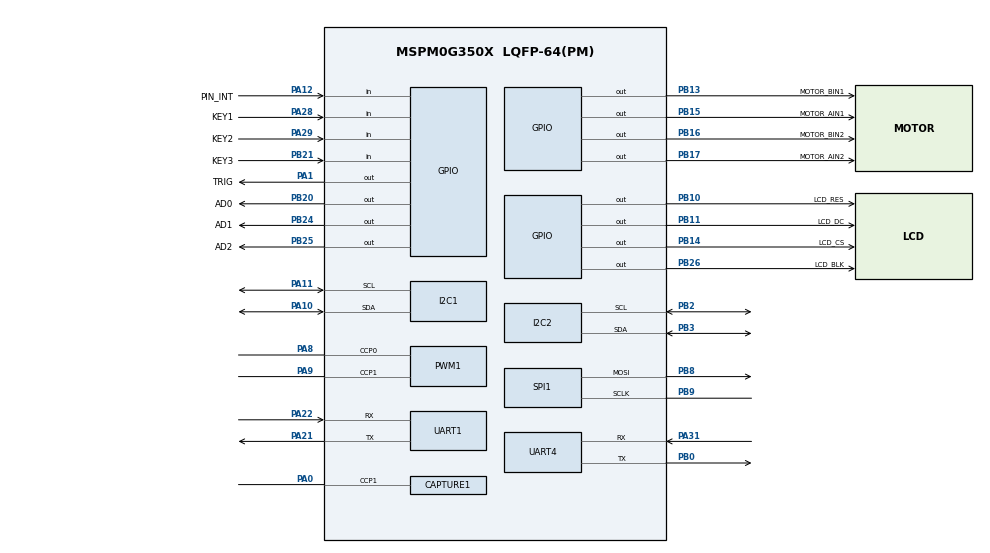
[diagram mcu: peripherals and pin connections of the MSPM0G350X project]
/**
 * @cliArgs --device "MSPM0G350X" --part "Default" --package "LQFP-64(PM)" --product "mspm0_sdk@2.10.00.04"
 * @versions {"tool":"1.26.2+4477"}
 */

/**
 * Import the modules used in this configuration.
 */
const ADC12    = scripting.addModule("/ti/driverlib/ADC12", {}, false);
const ADC121   = ADC12.addInstance();
const CAPTURE  = scripting.addModule("/ti/driverlib/CAPTURE", {}, false);
const CAPTURE1 = CAPTURE.addInstance();
const GPIO     = scripting.addModule("/ti/driverlib/GPIO", {}, false);
const GPIO1    = GPIO.addInstance();
const GPIO2    = GPIO.addInstance();
const GPIO3    = GPIO.addInstance();
const GPIO4    = GPIO.addInstance();
const GPIO5    = GPIO.addInstance();
const GPIO6    = GPIO.addInstance();
const GPIO7    = GPIO.addInstance();
const GPIO8    = GPIO.addInstance();
const I2C      = scripting.addModule("/ti/driverlib/I2C", {}, false);
const I2C1     = I2C.addInstance();
const I2C2     = I2C.addInstance();
const PWM      = scripting.addModule("/ti/driverlib/PWM", {}, false);
const PWM1     = PWM.addInstance();
const SPI      = scripting.addModule("/ti/driverlib/SPI", {}, false);
const SPI1     = SPI.addInstance();
const SYSCTL   = scripting.addModule("/ti/driverlib/SYSCTL");
const TIMER    = scripting.addModule("/ti/driverlib/TIMER", {}, false);
const TIMER1   = TIMER.addInstance();
const UART     = scripting.addModule("/ti/driverlib/UART", {}, false);
const UART1    = UART.addInstance();
const UART2    = UART.addInstance();
const UART3    = UART.addInstance();
const UART4    = UART.addInstance();

/**
 * Write custom configuration values to the imported modules.
 */
const divider6       = system.clockTree["PLL_CLK2X_DIV"];
divider6.divideValue = 4;

const divider7       = system.clockTree["PLL_PDIV"];
divider7.divideValue = 2;

const divider9       = system.clockTree["UDIV"];
divider9.divideValue = 2;

const multiplier2         = system.clockTree["PLL_QDIV"];
multiplier2.multiplyValue = 10;

const mux8       = system.clockTree["HSCLKMUX"];
mux8.inputSelect = "HSCLKMUX_SYSPLL2X";

ADC121.$name                      = "ADC12_0";
ADC121.sampleTime0                = "2 us";
ADC121.sampClkDiv                 = "DL_ADC12_CLOCK_DIVIDE_8";
ADC121.enabledInterrupts          = ["DL_ADC12_INTERRUPT_MEM0_RESULT_LOADED"];
ADC121.adcMem0_name               = "ADC_CH0";
ADC121.repeatMode                 = true;
ADC121.peripheral.$assign         = "ADC0";
ADC121.peripheral.adcPin0.$assign = "PA27";
ADC121.adcPin0Config.$name        = "ti_driverlib_gpio_GPIOPinGeneric8";

const Board = scripting.addModule("/ti/driverlib/Board", {}, false);

CAPTURE1.$name                      = "HC_SR04_CAPTURE";
CAPTURE1.ccIndex                    = 1;
CAPTURE1.captMode                   = "COMBINED";
CAPTURE1.timerClkPrescale           = 32;
CAPTURE1.timerPeriod                = "65.536 ms";
CAPTURE1.interrupts                 = ["CC1_DN"];
CAPTURE1.interruptPriority          = "2";
CAPTURE1.timerStartTimer            = true;
CAPTURE1.peripheral.$assign         = "TIMG8";
CAPTURE1.peripheral.ccp1Pin.$assign = "PA0";
CAPTURE1.ccp1PinConfig.$name        = "ti_driverlib_gpio_GPIOPinGeneric15";

GPIO1.port                               = "PORTA";
GPIO1.$name                              = "KEY_INPUT_A";
GPIO1.associatedPins.create(2);
GPIO1.associatedPins[0].$name            = "KEY1";
GPIO1.associatedPins[0].direction        = "INPUT";
GPIO1.associatedPins[0].internalResistor = "PULL_UP";
GPIO1.associatedPins[0].pin.$assign      = "PA28";
GPIO1.associatedPins[1].$name            = "KEY2";
GPIO1.associatedPins[1].direction        = "INPUT";
GPIO1.associatedPins[1].internalResistor = "PULL_UP";
GPIO1.associatedPins[1].pin.$assign      = "PA29";

GPIO2.$name                         = "MOTOR_AIN";
GPIO2.port                          = "PORTB";
GPIO2.associatedPins.create(2);
GPIO2.associatedPins[0].$name       = "MOTOR_AIN1";
GPIO2.associatedPins[0].pin.$assign = "PB15";
GPIO2.associatedPins[1].$name       = "MOTOR_AIN2";
GPIO2.associatedPins[1].pin.$assign = "PB17";

GPIO3.$name                         = "MOTOR_BIN";
GPIO3.port                          = "PORTB";
GPIO3.associatedPins.create(2);
GPIO3.associatedPins[0].$name       = "MOTOR_BIN1";
GPIO3.associatedPins[0].pin.$assign = "PB13";
GPIO3.associatedPins[1].$name       = "MOTOR_BIN2";
GPIO3.associatedPins[1].pin.$assign = "PB16";

GPIO4.$name                         = "Gray_Address";
GPIO4.port                          = "PORTB";
GPIO4.associatedPins.create(3);
GPIO4.associatedPins[0].$name       = "AD0";
GPIO4.associatedPins[0].pin.$assign = "PB20";
GPIO4.associatedPins[1].$name       = "AD1";
GPIO4.associatedPins[1].pin.$assign = "PB24";
GPIO4.associatedPins[2].$name       = "AD2";
GPIO4.associatedPins[2].pin.$assign = "PB25";

GPIO5.$name                               = "GPIO_MPU6050";
GPIO5.port                                = "PORTA";
GPIO5.associatedPins[0].$name             = "PIN_INT";
GPIO5.associatedPins[0].direction         = "INPUT";
GPIO5.associatedPins[0].interruptEn       = true;
GPIO5.associatedPins[0].interruptPriority = "1";
GPIO5.associatedPins[0].polarity          = "RISE";
GPIO5.associatedPins[0].pin.$assign       = "PA12";

GPIO6.$name                          = "GPIO_LCD_CONTROL";
GPIO6.port                           = "PORTB";
GPIO6.associatedPins.create(4);
GPIO6.associatedPins[0].$name        = "LCD_RES";
GPIO6.associatedPins[0].initialValue = "SET";
GPIO6.associatedPins[0].pin.$assign  = "PB10";
GPIO6.associatedPins[1].$name        = "LCD_DC";
GPIO6.associatedPins[1].initialValue = "SET";
GPIO6.associatedPins[1].pin.$assign  = "PB11";
GPIO6.associatedPins[2].$name        = "LCD_CS";
GPIO6.associatedPins[2].initialValue = "SET";
GPIO6.associatedPins[2].pin.$assign  = "PB14";
GPIO6.associatedPins[3].$name        = "LCD_BLK";
GPIO6.associatedPins[3].pin.$assign  = "PB26";

GPIO7.$name                              = "KEY_INPUT_B";
GPIO7.port                               = "PORTB";
GPIO7.portSegment                        = "Upper";
GPIO7.associatedPins[0].$name            = "KEY3";
GPIO7.associatedPins[0].direction        = "INPUT";
GPIO7.associatedPins[0].internalResistor = "PULL_UP";
GPIO7.associatedPins[0].pin.$assign      = "PB21";

GPIO8.$name                         = "HC_SR04_TRIG";
GPIO8.port                          = "PORTA";
GPIO8.associatedPins[0].$name       = "TRIG";
GPIO8.associatedPins[0].pin.$assign = "PA1";

I2C1.$name                             = "I2C_OLED";
I2C1.basicEnableController             = true;
I2C1.basicControllerStandardBusSpeed   = "Fast";
I2C1.peripheral.$assign                = "I2C0";
I2C1.peripheral.sdaPin.$assign         = "PA10";
I2C1.peripheral.sclPin.$assign         = "PA11";
I2C1.sdaPinConfig.$name                = "ti_driverlib_gpio_GPIOPinGeneric2";
I2C1.sdaPinConfig.hideOutputInversion  = scripting.forceWrite(false);
I2C1.sdaPinConfig.onlyInternalResistor = scripting.forceWrite(false);
I2C1.sdaPinConfig.passedPeripheralType = scripting.forceWrite("Digital");
I2C1.sclPinConfig.$name                = "ti_driverlib_gpio_GPIOPinGeneric3";
I2C1.sclPinConfig.hideOutputInversion  = scripting.forceWrite(false);
I2C1.sclPinConfig.onlyInternalResistor = scripting.forceWrite(false);
I2C1.sclPinConfig.passedPeripheralType = scripting.forceWrite("Digital");

I2C2.$name                             = "I2C_MPU6050";
I2C2.basicEnableController             = true;
I2C2.basicControllerStandardBusSpeed   = "Fast";
I2C2.peripheral.$assign                = "I2C1";
I2C2.peripheral.sdaPin.$assign         = "PB3";
I2C2.peripheral.sclPin.$assign         = "PB2";
I2C2.sdaPinConfig.$name                = "ti_driverlib_gpio_GPIOPinGeneric4";
I2C2.sdaPinConfig.hideOutputInversion  = scripting.forceWrite(false);
I2C2.sdaPinConfig.onlyInternalResistor = scripting.forceWrite(false);
I2C2.sdaPinConfig.passedPeripheralType = scripting.forceWrite("Digital");
I2C2.sclPinConfig.$name                = "ti_driverlib_gpio_GPIOPinGeneric5";
I2C2.sclPinConfig.hideOutputInversion  = scripting.forceWrite(false);
I2C2.sclPinConfig.onlyInternalResistor = scripting.forceWrite(false);
I2C2.sclPinConfig.passedPeripheralType = scripting.forceWrite("Digital");

PWM1.$name                              = "PWM_MOTOR";
PWM1.pwmMode                            = "EDGE_ALIGN_UP";
PWM1.timerStartTimer                    = true;
PWM1.peripheral.$assign                 = "TIMA0";
PWM1.peripheral.ccp0Pin.$assign         = "PA8";
PWM1.peripheral.ccp1Pin.$assign         = "PA9";
PWM1.PWM_CHANNEL_0.$name                = "ti_driverlib_pwm_PWMTimerCC0";
PWM1.PWM_CHANNEL_1.$name                = "ti_driverlib_pwm_PWMTimerCC1";
PWM1.ccp0PinConfig.direction            = scripting.forceWrite("OUTPUT");
PWM1.ccp0PinConfig.hideOutputInversion  = scripting.forceWrite(false);
PWM1.ccp0PinConfig.onlyInternalResistor = scripting.forceWrite(false);
PWM1.ccp0PinConfig.passedPeripheralType = scripting.forceWrite("Digital");
PWM1.ccp0PinConfig.$name                = "ti_driverlib_gpio_GPIOPinGeneric0";
PWM1.ccp1PinConfig.direction            = scripting.forceWrite("OUTPUT");
PWM1.ccp1PinConfig.hideOutputInversion  = scripting.forceWrite(false);
PWM1.ccp1PinConfig.onlyInternalResistor = scripting.forceWrite(false);
PWM1.ccp1PinConfig.passedPeripheralType = scripting.forceWrite("Digital");
PWM1.ccp1PinConfig.$name                = "ti_driverlib_gpio_GPIOPinGeneric1";

SPI1.$name                              = "SPI_LCD";
SPI1.frameFormat                        = "MOTO3";
SPI1.direction                          = "PICO";
SPI1.sclkPinConfig.direction            = scripting.forceWrite("OUTPUT");
SPI1.sclkPinConfig.onlyInternalResistor = scripting.forceWrite(false);
SPI1.sclkPinConfig.passedPeripheralType = scripting.forceWrite("Digital");
SPI1.sclkPinConfig.$name                = "ti_driverlib_gpio_GPIOPinGeneric13";
SPI1.mosiPinConfig.direction            = scripting.forceWrite("OUTPUT");
SPI1.mosiPinConfig.hideOutputInversion  = scripting.forceWrite(false);
SPI1.mosiPinConfig.onlyInternalResistor = scripting.forceWrite(false);
SPI1.mosiPinConfig.passedPeripheralType = scripting.forceWrite("Digital");
SPI1.mosiPinConfig.$name                = "ti_driverlib_gpio_GPIOPinGeneric14";
SPI1.peripheral.$assign                 = "SPI1";
SPI1.peripheral.sclkPin.$assign         = "PB9";
SPI1.peripheral.mosiPin.$assign         = "PB8";

SYSCTL.forceDefaultClkConfig = true;

TIMER1.timerMode          = "PERIODIC";
TIMER1.timerStartTimer    = true;
TIMER1.$name              = "CONTROL_TIMER";
TIMER1.timerPeriod        = "10ms";
TIMER1.timerClkDiv        = 8;
TIMER1.interrupts         = ["ZERO"];
TIMER1.interruptPriority  = "2";
TIMER1.peripheral.$assign = "TIMA1";

UART1.targetBaudRate                    = 115200;
UART1.enabledInterrupts                 = ["DMA_DONE_TX","EOT_DONE"];
UART1.interruptPriority                 = "3";
UART1.enableFIFO                        = true;
UART1.txFifoThreshold                   = "DL_UART_TX_FIFO_LEVEL_ONE_ENTRY";
UART1.enabledDMATXTriggers              = "DL_UART_DMA_INTERRUPT_TX";
UART1.$name                             = "UART_TEST";
UART1.peripheral.rxPin.$assign          = "PA22";
UART1.peripheral.txPin.$assign          = "PA21";
UART1.txPinConfig.direction             = scripting.forceWrite("OUTPUT");
UART1.txPinConfig.hideOutputInversion   = scripting.forceWrite(false);
UART1.txPinConfig.onlyInternalResistor  = scripting.forceWrite(false);
UART1.txPinConfig.passedPeripheralType  = scripting.forceWrite("Digital");
UART1.txPinConfig.$name                 = "ti_driverlib_gpio_GPIOPinGeneric6";
UART1.rxPinConfig.hideOutputInversion   = scripting.forceWrite(false);
UART1.rxPinConfig.onlyInternalResistor  = scripting.forceWrite(false);
UART1.rxPinConfig.passedPeripheralType  = scripting.forceWrite("Digital");
UART1.rxPinConfig.$name                 = "ti_driverlib_gpio_GPIOPinGeneric7";
UART1.DMA_CHANNEL_TX.$name              = "DMA_CH0";
UART1.DMA_CHANNEL_TX.addressMode        = "b2f";
UART1.DMA_CHANNEL_TX.dstLength          = "BYTE";
UART1.DMA_CHANNEL_TX.srcLength          = "BYTE";
UART1.DMA_CHANNEL_TX.peripheral.$assign = "DMA_CH0";

UART2.$name                            = "UART_MAXI";
UART2.targetBaudRate                   = 115200;
UART2.peripheral.$assign               = "UART1";
UART2.txPinConfig.direction            = scripting.forceWrite("OUTPUT");
UART2.txPinConfig.hideOutputInversion  = scripting.forceWrite(false);
UART2.txPinConfig.onlyInternalResistor = scripting.forceWrite(false);
UART2.txPinConfig.passedPeripheralType = scripting.forceWrite("Digital");
UART2.txPinConfig.$name                = "ti_driverlib_gpio_GPIOPinGeneric9";
UART2.rxPinConfig.hideOutputInversion  = scripting.forceWrite(false);
UART2.rxPinConfig.onlyInternalResistor = scripting.forceWrite(false);
UART2.rxPinConfig.passedPeripheralType = scripting.forceWrite("Digital");
UART2.rxPinConfig.$name                = "ti_driverlib_gpio_GPIOPinGeneric10";

UART3.$name                            = "UART_BLUETOOTH";
UART3.targetBaudRate                   = 115200;
UART3.enabledInterrupts                = ["RX"];
UART3.interruptPriority                = "3";
UART3.enableFIFO                       = true;
UART3.rxFifoThreshold                  = "DL_UART_RX_FIFO_LEVEL_ONE_ENTRY";
UART3.peripheral.$assign               = "UART3";
UART3.txPinConfig.direction            = scripting.forceWrite("OUTPUT");
UART3.txPinConfig.hideOutputInversion  = scripting.forceWrite(false);
UART3.txPinConfig.onlyInternalResistor = scripting.forceWrite(false);
UART3.txPinConfig.passedPeripheralType = scripting.forceWrite("Digital");
UART3.txPinConfig.$name                = "ti_driverlib_gpio_GPIOPinGeneric11";
UART3.rxPinConfig.hideOutputInversion  = scripting.forceWrite(false);
UART3.rxPinConfig.onlyInternalResistor = scripting.forceWrite(false);
UART3.rxPinConfig.passedPeripheralType = scripting.forceWrite("Digital");
UART3.rxPinConfig.$name                = "ti_driverlib_gpio_GPIOPinGeneric12";

UART4.$name                            = "UART_GYRO";
UART4.targetBaudRate                   = 115200;
UART4.enabledInterrupts                = ["RX"];
UART4.interruptPriority                = "3";
UART4.enableFIFO                       = true;
UART4.rxFifoThreshold                  = "DL_UART_RX_FIFO_LEVEL_ONE_ENTRY";
UART4.peripheral.$assign               = "UART0";
UART4.peripheral.rxPin.$assign         = "PA31";
UART4.peripheral.txPin.$assign         = "PB0";
UART4.txPinConfig.$name                = "ti_driverlib_gpio_GPIOPinGeneric16";
UART4.txPinConfig.direction            = scripting.forceWrite("OUTPUT");
UART4.txPinConfig.hideOutputInversion  = scripting.forceWrite(false);
UART4.txPinConfig.onlyInternalResistor = scripting.forceWrite(false);
UART4.txPinConfig.passedPeripheralType = scripting.forceWrite("Digital");
UART4.rxPinConfig.$name                = "ti_driverlib_gpio_GPIOPinGeneric17";
UART4.rxPinConfig.hideOutputInversion  = scripting.forceWrite(false);
UART4.rxPinConfig.onlyInternalResistor = scripting.forceWrite(false);
UART4.rxPinConfig.passedPeripheralType = scripting.forceWrite("Digital");

/**
 * Pinmux solution for unlocked pins/peripherals. This ensures that minor changes to the automatic solver in a future
 * version of the tool will not impact the pinmux you originally saw.  These lines can be completely deleted in order to
 * re-solve from scratch.
 */
Board.peripheral.$suggestSolution          = "DEBUGSS";
Board.peripheral.swclkPin.$suggestSolution = "PA20";
Board.peripheral.swdioPin.$suggestSolution = "PA19";
SYSCTL.peripheral.$suggestSolution         = "SYSCTL";
UART1.peripheral.$suggestSolution          = "UART2";
UART2.peripheral.rxPin.$suggestSolution    = "PA18";
UART2.peripheral.txPin.$suggestSolution    = "PA17";
UART3.peripheral.rxPin.$suggestSolution    = "PA13";
UART3.peripheral.txPin.$suggestSolution    = "PA14";
UART4.peripheral.$suggestSolution          = "UART0";
UART4.peripheral.rxPin.$suggestSolution    = "PA31";
UART4.peripheral.txPin.$suggestSolution    = "PB0";
